# DEBUGSS_DEBUGSS_ATB_REPLICATOR_CFG_CXATBREPLICATOR_CFG_00073C024000h register map
Vendor: Texas Instruments
Peripheral module from a debugger description file (folder am62L).
Registers are 32-bit, read-only, reset 0x0 unless marked. A register's access mark holds for its fields unless they carry their own. Offsets are as the file gives them; lines under a group give offsets from that group; [hi:lo] are bit positions; {n}, {i} and the like mark numbered series; 'fields as' and 'values as' point back to an identical list; <NAME> marks a mode.

## DEBUGSS_ATB_REPLICATOR_CFG_CXATBREPLICATOR_CFG
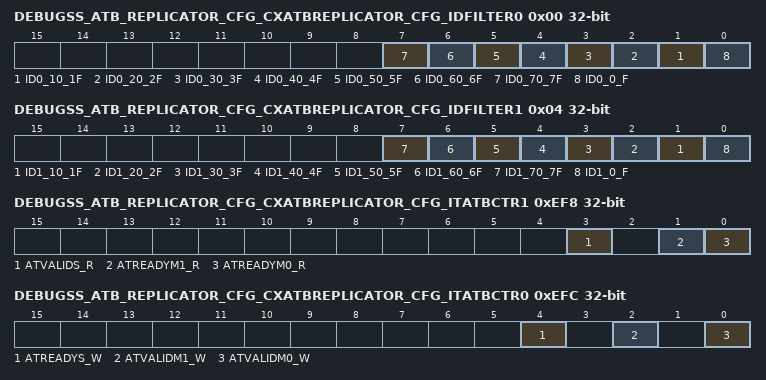
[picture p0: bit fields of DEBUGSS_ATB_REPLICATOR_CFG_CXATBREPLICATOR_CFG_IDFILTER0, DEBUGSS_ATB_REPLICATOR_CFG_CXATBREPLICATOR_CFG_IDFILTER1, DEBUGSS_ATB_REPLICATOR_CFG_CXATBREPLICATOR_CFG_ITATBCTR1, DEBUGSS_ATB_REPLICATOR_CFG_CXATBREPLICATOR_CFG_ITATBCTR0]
0x00 DEBUGSS_ATB_REPLICATOR_CFG_CXATBREPLICATOR_CFG_IDFILTER0 rw — Allows the setting of ID filter for Master 0.
  [n] ID0_{10n}_{n}F (n=1..7) — Enable or disable ID filitering for id's {0x0+0x10*n} to {0xF+0x10*n}
  [0] ID0_0_F — Enable or disable ID filitering for id's 0x0 to 0xF
0x04 DEBUGSS_ATB_REPLICATOR_CFG_CXATBREPLICATOR_CFG_IDFILTER1 rw — Allows the setting of ID filter for Master 1.
  [n] ID1_{10n}_{n}F (n=1..7) — Enable or disable ID filitering for id's {0x0+0x10*n} to {0xF+0x10*n}
  [0] ID1_0_F — Enable or disable ID filitering for id's 0x0 to 0xF
0xEF8 DEBUGSS_ATB_REPLICATOR_CFG_CXATBREPLICATOR_CFG_ITATBCTR1 — Returns the value of the ATREADYM0, ATREADYM1 and ATVALIDS inputs in integration mode.
  [3] ATVALIDS_R — Reads the value of the ATVALIDS input :
  [1] ATREADYM1_R — Reads the value of the ATREADYM1 input :
  [0] ATREADYM0_R — Reads the value of the ATREADYM0 input :
0xEFC DEBUGSS_ATB_REPLICATOR_CFG_CXATBREPLICATOR_CFG_ITATBCTR0 rw — Controls the value of the ATVALIDM0, ATVALIDM1 and ATREADYS outputs in integration mode.
  [4] ATREADYS_W — Sets the value of the ATREADYS output :
  [2] ATVALIDM1_W — Sets the value of the ATVALIDM1 output :
  [0] ATVALIDM0_W — Sets the value of the ATVALIDM0 output :
0xF00 DEBUGSS_ATB_REPLICATOR_CFG_CXATBREPLICATOR_CFG_ITCTRL rw — Used to enable topology detection. See the CoreSight Architecture Specification for more information. This register enables the component to switch from a functional mode, the default behavior, to integration mode where the inputs and outputs of the component can be directly controlled for integration testing and topology solving. p/ > Note : When a device has been in integration mode, it might not function with the original behavior. After performing integration or topology detection, you must reset the system to ensure correct behavior of CoreSight and other connected system components that are affected by the integration or topology detection.
  [0] INTEGRATION_MODE — Enables the component to switch from functional mode to integration mode and back. If no integration functionality is implemented, this register must read as zero.
0xFA0 DEBUGSS_ATB_REPLICATOR_CFG_CXATBREPLICATOR_CFG_CLAIMSET rw reset 0xF — This is used in conjunction with Claim Tag Clear Register, CLAIMCLR. This register forms one half of the Claim Tag value. This location allows individual bits to be set, write, and returns the number of bits that can be set, read.
  [3:0] CLAIMSET — This claim tag bit is implemented
0xFA4 DEBUGSS_ATB_REPLICATOR_CFG_CXATBREPLICATOR_CFG_CLAIMCLR rw — This register is used in conjunction with Claim Tag Set Register, CLAIMSET. This register forms one half of the Claim Tag value. This location enables individual bits to be cleared, write, and returns the current Claim Tag value, read.
  [3:0] CLAIMCLR — The value present reflects the current setting of the Claim Tag.
0xFB0 DEBUGSS_ATB_REPLICATOR_CFG_CXATBREPLICATOR_CFG_LAR rw — This is used to enable write access to device registers.
  [31:0] ACCESS_W — A write of 0xC5ACCE55 enables further write access to this device. An invalid write has the affect of removing write access.
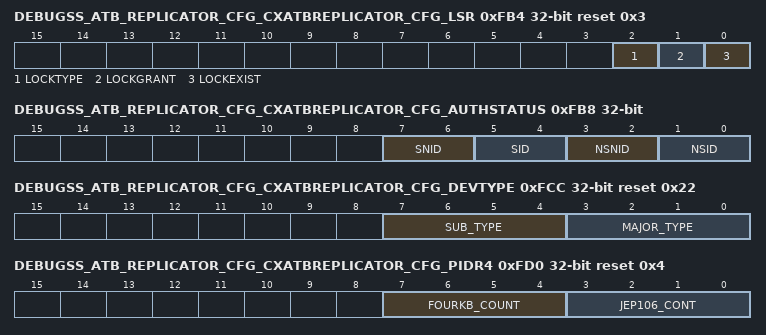
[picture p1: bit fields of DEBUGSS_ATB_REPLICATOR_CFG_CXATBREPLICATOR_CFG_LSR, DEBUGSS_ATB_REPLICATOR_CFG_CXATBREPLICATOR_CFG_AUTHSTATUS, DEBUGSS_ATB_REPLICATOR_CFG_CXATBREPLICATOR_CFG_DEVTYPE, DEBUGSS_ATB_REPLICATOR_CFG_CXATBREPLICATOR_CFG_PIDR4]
0xFB4 DEBUGSS_ATB_REPLICATOR_CFG_CXATBREPLICATOR_CFG_LSR reset 0x3 — This indicates the status of the lock control mechanism. This lock prevents accidental writes by code under debug. This register must always be present although there might not be any lock access control mechanism. The lock mechanism, where present and locked, must block write accesses to any control register, except the Lock Access Register. For most components this covers all registers except for the Lock Access Register, 0xFB0.
  [2] LOCKTYPE — Indicates if the Lock Access Register, 0xFB0, is implemented as 8-bit or 32-bit.
  [1] LOCKGRANT — Returns the current status of the Lock.
  [0] LOCKEXIST — Indicates that a lock control mechanism exists for this device.
0xFB8 DEBUGSS_ATB_REPLICATOR_CFG_CXATBREPLICATOR_CFG_AUTHSTATUS — Reports the required security level and current status of those enables. Where functionality changes on a given security level then this change in status must be reported in this register
  [7:6] SNID — Indicates the security level for secure non-invasive debug
  [5:4] SID — Indicates the security level for secure invasive debug
  [3:2] NSNID — Indicates the security level for non-secure non-invasive debug
  [1:0] NSID — Indicates the security level for non-secure invasive debug
0xFC8 DEBUGSS_ATB_REPLICATOR_CFG_CXATBREPLICATOR_CFG_DEVID reset 0x2 — Indicates the capabilities of the CoreSight Replicator.
  [3:0] PORTNUM — This value indicates the number of master ports implemented.
0xFCC DEBUGSS_ATB_REPLICATOR_CFG_CXATBREPLICATOR_CFG_DEVTYPE reset 0x22 — Provides a debugger with information about the component when the Part Number field is not recognized. The debugger can then report this information.
  [7:4] SUB_TYPE — Sub-classification within the major category :
  [3:0] MAJOR_TYPE — Major classification grouping for this debug or trace component :
0xFD0 DEBUGSS_ATB_REPLICATOR_CFG_CXATBREPLICATOR_CFG_PIDR4 reset 0x4 — Part of the set of Peripheral Identification registers. Contains part of the designer identity and the memory footprint indicator.
  [7:4] FOURKB_COUNT — This is a 4-bit value that indicates the total contiguous size of the memory window used by this component in powers of 2 from the standard 4KB. If a component only requires the standard 4KB, this must read as 0x0, 4KB only. For 8KB set to 0x1, for 16KB set to 0x2, for 32KB set to 0x3, and so on.
  [3:0] JEP106_CONT — JEDEC continuation code indicating the designer of the component, together with the identity code.
0xFE0 DEBUGSS_ATB_REPLICATOR_CFG_CXATBREPLICATOR_CFG_PIDR0 reset 0x9 — Part of the set of Peripheral Identification registers. Contains part of the designer specific part number.
  [7:0] PART_NUMBER_BITS7TO0 — Bits [7 : 0] of the component part number. This is selected by the designer of the component.
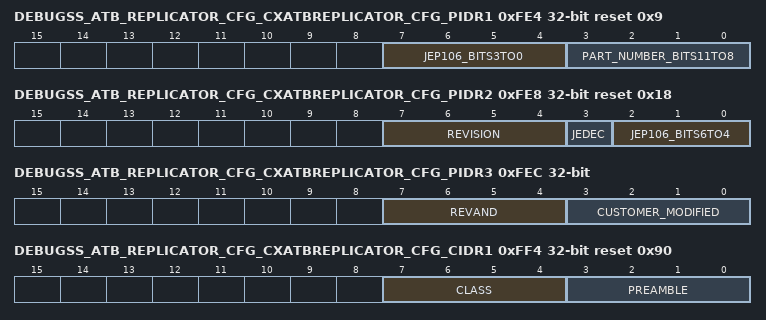
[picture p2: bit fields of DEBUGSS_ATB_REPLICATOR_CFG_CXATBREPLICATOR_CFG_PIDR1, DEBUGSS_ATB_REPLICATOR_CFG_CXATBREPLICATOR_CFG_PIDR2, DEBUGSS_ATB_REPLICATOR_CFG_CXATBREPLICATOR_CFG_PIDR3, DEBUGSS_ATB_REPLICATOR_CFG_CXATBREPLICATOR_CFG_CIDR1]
0xFE4 DEBUGSS_ATB_REPLICATOR_CFG_CXATBREPLICATOR_CFG_PIDR1 reset 0x9 — Part of the set of Peripheral Identification registers. Contains part of the designer specific part number and part of the designer identity.
  [7:4] JEP106_BITS3TO0 — Bits [3 : 0] of the JEDEC identity code indicating the designer of the component, together with the continuation code.
  [3:0] PART_NUMBER_BITS11TO8 — Bits [11 : 8] of the component part number. This is selected by the designer of the component.
0xFE8 DEBUGSS_ATB_REPLICATOR_CFG_CXATBREPLICATOR_CFG_PIDR2 reset 0x18 — Part of the set of Peripheral Identification registers. Contains part of the designer identity and the product revision.
  [7:4] REVISION — The Revision field is an incremental value starting at 0x0 for the first design of this component. This only increases by 1 for both major and minor revisions and is used as a look-up to establish the exact major and minor revision.
  [3] JEDEC — Always set. Indicates that a JEDEC assigned value is used.
  [2:0] JEP106_BITS6TO4 — Bits [6 : 4] of the JEDEC identity code indicating the designer of the component, together with the continuation code.
0xFEC DEBUGSS_ATB_REPLICATOR_CFG_CXATBREPLICATOR_CFG_PIDR3 — Part of the set of Peripheral Identification registers. Contains the RevAnd and Customer Modified fields.
  [7:4] REVAND — This field indicates minor errata fixes specific to this design, for example metal fixes after implementation. In most cases this field is zero. It is recommended that component designers ensure this field can be changed by a metal fix if required, for example by driving it from registers that reset to zero.
  [3:0] CUSTOMER_MODIFIED — Where the component is reusable IP, this value indicates if the customer has modified the behavior of the component. In most cases this field is zero.
0xFF0 DEBUGSS_ATB_REPLICATOR_CFG_CXATBREPLICATOR_CFG_CIDR0 reset 0xD — Reserved Reserved Reserved A component identification register, that indicates that the identification registers are present.
  [7:0] PREAMBLE — Contains bits [24 : 31] of the component identification.
0xFF4 DEBUGSS_ATB_REPLICATOR_CFG_CXATBREPLICATOR_CFG_CIDR1 reset 0x90 — A component identification register, that indicates that the identification registers are present. This register also indicates the component class.
  [7:4] CLASS — Class of the component, for example, ROM table or CoreSight component.
  [3:0] PREAMBLE — Contains bits [19 : 16] of the component identification.
0xFF8 DEBUGSS_ATB_REPLICATOR_CFG_CXATBREPLICATOR_CFG_CIDR2 reset 0x5 — A component identification register, that indicates that the identification registers are present.
  [7:0] PREAMBLE — Contains bits [15 : 8] of the component identification.
0xFFC DEBUGSS_ATB_REPLICATOR_CFG_CXATBREPLICATOR_CFG_CIDR3 reset 0xB1 — A component identification register, that indicates that the identification registers are present.
  [7:0] PREAMBLE — Contains bits [7 : 0] of the component identification.
